# C7X256V1_ECC_AGGR_ECC_AGGR register map
Vendor: Texas Instruments
Peripheral module from a debugger description file (folder J722S).
Registers are 32-bit, access not given, reset 0x0 unless marked. A register's access mark holds for its fields unless they carry their own. Offsets are as the file gives them; lines under a group give offsets from that group; [hi:lo] are bit positions; {n}, {i} and the like mark numbered series; 'fields as' and 'values as' point back to an identical list; <NAME> marks a mode.

## C7X256V1_ECC_AGGR_ECC_AGGR
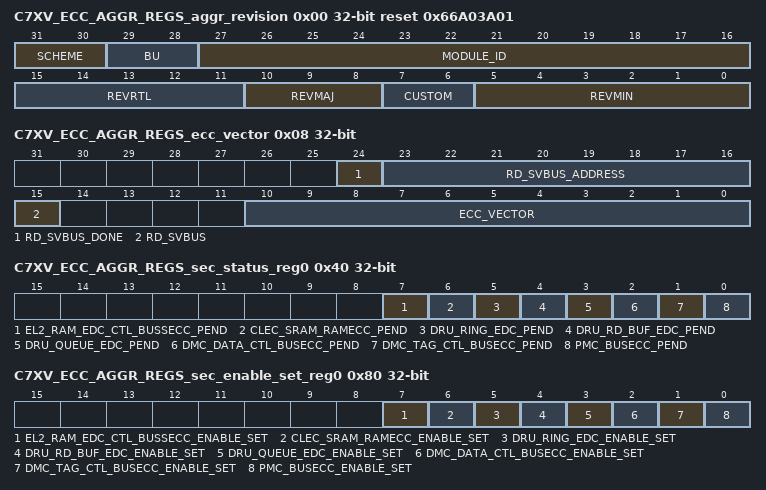
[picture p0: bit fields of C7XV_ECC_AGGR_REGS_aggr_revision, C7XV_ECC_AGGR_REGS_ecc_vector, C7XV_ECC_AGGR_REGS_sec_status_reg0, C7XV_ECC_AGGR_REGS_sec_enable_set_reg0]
0x00 C7XV_ECC_AGGR_REGS_aggr_revision ro reset 0x66A03A01 — Revision parameters
  [31:30] SCHEME
  [29:28] BU
  [27:16] MODULE_ID
  [15:11] REVRTL — RTL version
  [10:8] REVMAJ — Major version
  [7:6] CUSTOM — Custom version
  [5:0] REVMIN — Minor version
0x08 C7XV_ECC_AGGR_REGS_ecc_vector — ECC Vector Register
  [24] RD_SVBUS_DONE — Status to indicate if read on serial VBUS is complete, write of any value will clear this bit. (access R/W1TC)
  [23:16] RD_SVBUS_ADDRESS rw — Read address
  [15] RD_SVBUS — Write 1 to trigger a read on the serial VBUS (access R/W1TS)
  [10:0] ECC_VECTOR rw — Value written to select the corresponding ECC RAM for control or status
0x0C C7XV_ECC_AGGR_REGS_misc_status ro reset 0x8 — Misc Status
  [10:0] NUM_RAMS — Indicates the number of RAMS serviced by the ECC aggregator
0x10 C7XV_ECC_AGGR_REGS_reserved_svbus rw — Reference other documents that contain the ECC RAM wrapper and EDC controller serial vbus register sets.
  [31:0] DATA — Serial VBUS register data
0x3C C7XV_ECC_AGGR_REGS_sec_eoi_reg — EOI Register
  [0] EOI_WR — EOI Register (access R/W1TS)
0x40 C7XV_ECC_AGGR_REGS_sec_status_reg0 — Interrupt Status Register 0
  [7] EL2_RAM_EDC_CTL_BUSSECC_PEND — Interrupt Pending Status for el2_ram_edc_ctl_bussecc_pend (access R/W1TS)
  [6] CLEC_SRAM_RAMECC_PEND — Interrupt Pending Status for clec_sram_ramecc_pend (access R/W1TS)
  [5] DRU_RING_EDC_PEND — Interrupt Pending Status for dru_ring_edc_pend (access R/W1TS)
  [4] DRU_RD_BUF_EDC_PEND — Interrupt Pending Status for dru_rd_buf_edc_pend (access R/W1TS)
  [3] DRU_QUEUE_EDC_PEND — Interrupt Pending Status for dru_queue_edc_pend (access R/W1TS)
  [2] DMC_DATA_CTL_BUSECC_PEND — Interrupt Pending Status for dmc_data_ctl_busecc_pend (access R/W1TS)
  [1] DMC_TAG_CTL_BUSECC_PEND — Interrupt Pending Status for dmc_tag_ctl_busecc_pend (access R/W1TS)
  [0] PMC_BUSECC_PEND — Interrupt Pending Status for pmc_busecc_pend (access R/W1TS)
0x80 C7XV_ECC_AGGR_REGS_sec_enable_set_reg0 — Interrupt Enable Set Register 0
  [7] EL2_RAM_EDC_CTL_BUSSECC_ENABLE_SET — Interrupt Enable Set Register for el2_ram_edc_ctl_bussecc_pend (access R/W1TS)
  [6] CLEC_SRAM_RAMECC_ENABLE_SET — Interrupt Enable Set Register for clec_sram_ramecc_pend (access R/W1TS)
  [5] DRU_RING_EDC_ENABLE_SET — Interrupt Enable Set Register for dru_ring_edc_pend (access R/W1TS)
  [4] DRU_RD_BUF_EDC_ENABLE_SET — Interrupt Enable Set Register for dru_rd_buf_edc_pend (access R/W1TS)
  [3] DRU_QUEUE_EDC_ENABLE_SET — Interrupt Enable Set Register for dru_queue_edc_pend (access R/W1TS)
  [2] DMC_DATA_CTL_BUSECC_ENABLE_SET — Interrupt Enable Set Register for dmc_data_ctl_busecc_pend (access R/W1TS)
  [1] DMC_TAG_CTL_BUSECC_ENABLE_SET — Interrupt Enable Set Register for dmc_tag_ctl_busecc_pend (access R/W1TS)
  [0] PMC_BUSECC_ENABLE_SET — Interrupt Enable Set Register for pmc_busecc_pend (access R/W1TS)
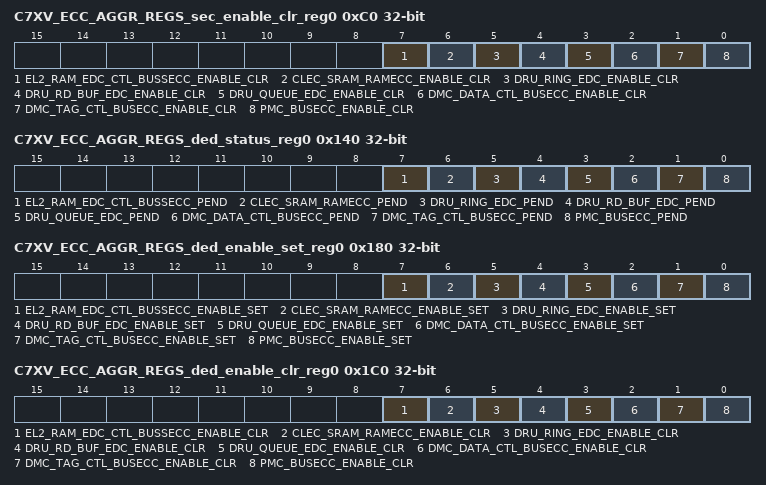
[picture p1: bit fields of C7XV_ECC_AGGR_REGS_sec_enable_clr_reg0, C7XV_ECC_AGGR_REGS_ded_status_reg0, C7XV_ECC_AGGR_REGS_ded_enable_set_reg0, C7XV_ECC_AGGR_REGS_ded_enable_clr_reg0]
0xC0 C7XV_ECC_AGGR_REGS_sec_enable_clr_reg0 — Interrupt Enable Clear Register 0
  [7] EL2_RAM_EDC_CTL_BUSSECC_ENABLE_CLR — Interrupt Enable Clear Register for el2_ram_edc_ctl_bussecc_pend (access R/W1TC)
  [6] CLEC_SRAM_RAMECC_ENABLE_CLR — Interrupt Enable Clear Register for clec_sram_ramecc_pend (access R/W1TC)
  [5] DRU_RING_EDC_ENABLE_CLR — Interrupt Enable Clear Register for dru_ring_edc_pend (access R/W1TC)
  [4] DRU_RD_BUF_EDC_ENABLE_CLR — Interrupt Enable Clear Register for dru_rd_buf_edc_pend (access R/W1TC)
  [3] DRU_QUEUE_EDC_ENABLE_CLR — Interrupt Enable Clear Register for dru_queue_edc_pend (access R/W1TC)
  [2] DMC_DATA_CTL_BUSECC_ENABLE_CLR — Interrupt Enable Clear Register for dmc_data_ctl_busecc_pend (access R/W1TC)
  [1] DMC_TAG_CTL_BUSECC_ENABLE_CLR — Interrupt Enable Clear Register for dmc_tag_ctl_busecc_pend (access R/W1TC)
  [0] PMC_BUSECC_ENABLE_CLR — Interrupt Enable Clear Register for pmc_busecc_pend (access R/W1TC)
0x13C C7XV_ECC_AGGR_REGS_ded_eoi_reg — EOI Register
  [0] EOI_WR — EOI Register (access R/W1TS)
0x140 C7XV_ECC_AGGR_REGS_ded_status_reg0 — Interrupt Status Register 0
  fields as C7XV_ECC_AGGR_REGS_sec_status_reg0
0x180 C7XV_ECC_AGGR_REGS_ded_enable_set_reg0 — Interrupt Enable Set Register 0
  fields as C7XV_ECC_AGGR_REGS_sec_enable_set_reg0
0x1C0 C7XV_ECC_AGGR_REGS_ded_enable_clr_reg0 — Interrupt Enable Clear Register 0
  fields as C7XV_ECC_AGGR_REGS_sec_enable_clr_reg0
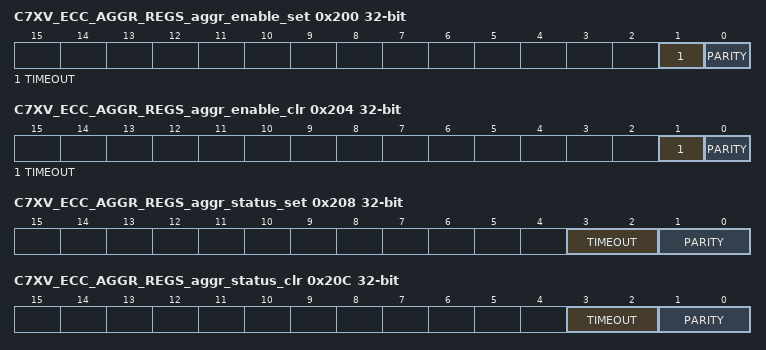
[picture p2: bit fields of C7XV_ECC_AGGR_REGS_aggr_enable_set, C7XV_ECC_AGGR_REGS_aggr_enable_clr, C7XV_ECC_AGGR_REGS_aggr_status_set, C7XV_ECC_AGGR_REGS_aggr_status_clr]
0x200 C7XV_ECC_AGGR_REGS_aggr_enable_set — AGGR interrupt enable set Register
  [1] TIMEOUT — interrupt enable set for svbus timeout errors (access R/W1TS)
  [0] PARITY — interrupt enable set for parity errors (access R/W1TS)
0x204 C7XV_ECC_AGGR_REGS_aggr_enable_clr — AGGR interrupt enable clear Register
  [1] TIMEOUT — interrupt enable clear for svbus timeout errors (access R/W1TC)
  [0] PARITY — interrupt enable clear for parity errors (access R/W1TC)
0x208 C7XV_ECC_AGGR_REGS_aggr_status_set — AGGR interrupt status set Register
  [3:2] TIMEOUT — interrupt status set for svbus timeout errors (access R/WI)
  [1:0] PARITY — interrupt status set for parity errors (access R/WI)
0x20C C7XV_ECC_AGGR_REGS_aggr_status_clr — AGGR interrupt status clear Register
  [3:2] TIMEOUT — interrupt status clear for svbus timeout errors (access R/WD)
  [1:0] PARITY — interrupt status clear for parity errors (access R/WD)
